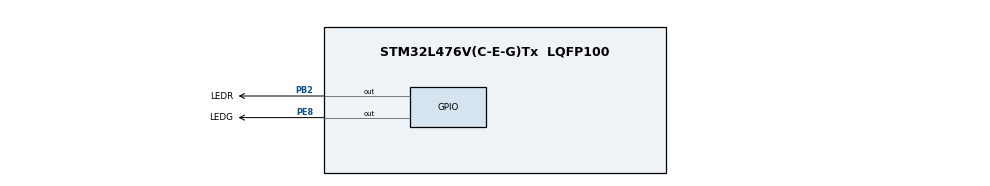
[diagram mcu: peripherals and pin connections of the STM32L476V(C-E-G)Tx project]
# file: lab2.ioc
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Mcu.Family=STM32L4
Mcu.Name=STM32L476V(C-E-G)Tx
Mcu.Package=LQFP100
NVIC.PriorityGroup=NVIC_PRIORITYGROUP_4
NVIC.RNG_IRQn=true\:0\:0\:false\:false\:true\:true\:true
NVIC.TIM2_IRQn=true\:0\:0\:false\:false\:true\:true\:true
NVIC.TIM4_IRQn=true\:0\:0\:false\:false\:true\:true\:true
PB2.GPIO_Label=LEDR
PB2.Signal=GPIO_Output
PE8.GPIO_Label=LEDG
PE8.Signal=GPIO_Output
ProjectManager.HeapSize=0x200
ProjectManager.StackSize=0x400
ProjectManager.TargetToolchain=MDK-ARM V5.27
RCC.ADCFreq_Value=32000000
RCC.CortexFreq_Value=4000000
RCC.HSE_VALUE=8000000
RCC.HSI_VALUE=16000000
RCC.LSE_VALUE=32768
RCC.MSI_VALUE=4000000
RCC.PLLSAI1N=16
RCC.PREFETCH_ENABLE=1
RCC.USBFreq_Value=32000000
RCC.VCOOutputFreq_Value=32000000
TIM2.AutoReloadPreload=TIM_AUTORELOAD_PRELOAD_ENABLE
TIM2.Period=4999
TIM2.Prescaler=399
TIM4.AutoReloadPreload=TIM_AUTORELOAD_PRELOAD_ENABLE
TIM4.Channel-Output\ Compare2\ No\ Output=TIM_CHANNEL_2
TIM4.OC2Preload=ENABLE
TIM4.Prescaler=399
TIM4.Pulse-Output\ Compare2\ No\ Output=9999
VP_RNG_VS_RNG.Mode=RNG_Activate
VP_TIM2_VS_ClockSourceINT.Mode=Internal
VP_TIM4_VS_ClockSourceINT.Mode=Internal
VP_TIM4_VS_no_output2.Mode=Output Compare2 No Output
board=STM32L476G-DISCO

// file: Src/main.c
/* USER CODE BEGIN Header */
/**
  ******************************************************************************
  * @file           : main.c
  * @brief          : Main program body
  ******************************************************************************
  * @attention
  *
  * <h2><center>&copy; Copyright (c) 2020 STMicroelectronics.
  * All rights reserved.</center></h2>
  *
  * This software component is licensed by ST under BSD 3-Clause license,
  * the "License"; You may not use this file except in compliance with the
  * License. You may obtain a copy of the License at:
  *                        opensource.org/licenses/BSD-3-Clause
  *
  ******************************************************************************
  */
/*

*/
/* USER CODE END Header */
#include "main.h"

/* USER CODE BEGIN Includes */
#include "stm32l476g_discovery.h"
#include "stm32l476g_discovery_glass_lcd.h"
#include "eeprom.h"
/* USER CODE END Includes */

typedef enum{DEFAULT, PURGATORY, START} state_Track;		//States for Reaction time tester

RNG_HandleTypeDef hrng;

TIM_HandleTypeDef htim2;
TIM_HandleTypeDef htim4;

/* USER CODE BEGIN PV */
// the emulated EEPROM can save 3 variables at these three addresses
uint16_t VirtAddVarTab[NB_OF_VAR] = {0x5555, 0x6666, 0x7777};
uint16_t counter = 0;
char lcd_buffer[6];
uint32_t rand_Num;
uint16_t time_Elapsed = 0;
uint16_t time_Elapsed_msec = 0;
uint16_t record_Time = 34463;
state_Track state = DEFAULT;

char time_Elapsed_String[6] = "000000";
char rand_Num_String[6] = "000000";
char record_Time_String[6] = "000000";

int sprintf(char *str, const char *format, ...);
/* USER CODE END PV */

void SystemClock_Config(void);
static void MX_GPIO_Init(void);
static void MX_TIM4_Init(void);
static void MX_TIM2_Init(void);
static void MX_RNG_Init(void);

/* USER CODE BEGIN 0 */

void HAL_TIM_PeriodElapsedCallback(TIM_HandleTypeDef *htim)
{
	time_Elapsed++;
	if (state == PURGATORY){
		if (time_Elapsed >= rand_Num){
			time_Elapsed = 0;
			BSP_LCD_GLASS_Clear();
			state = START;
		}
	}else if(state == START){
		BSP_LED_On(LED4);
		BSP_LED_On(LED5);
		time_Elapsed_msec = 10*time_Elapsed;
		sprintf(time_Elapsed_String, "%u", time_Elapsed_msec);
		BSP_LCD_GLASS_DisplayString((uint8_t*)time_Elapsed_String);
	}
}

//Handles frequency change of LED4
void HAL_TIM_OC_DelayElapsedCallback(TIM_HandleTypeDef * htim)
{
	if (state == DEFAULT){
		BSP_LED_Toggle(LED4);
		BSP_LED_Toggle(LED5);
	}else{
		BSP_LED_Off(LED4);
		BSP_LED_Off(LED5);
	}
	__HAL_TIM_SET_COUNTER(htim, 0x0000);
}
/* USER CODE END 0 */

int main(void)
{

  /* MCU Configuration--------------------------------------------------------*/

  /* Reset of all peripherals, Initializes the Flash interface and the Systick. */
  HAL_Init();

  /* Configure the system clock*/
  SystemClock_Config();

	HAL_InitTick(0x0000); //set the systick interrupt priority to the highest

	BSP_LED_Init(LED4);
	BSP_LED_Init(LED5);

	BSP_LCD_GLASS_Init();

	BSP_JOY_Init(JOY_MODE_EXTI);

  /* Initialize all configured peripherals */
  MX_GPIO_Init();
  MX_TIM4_Init();
  MX_TIM2_Init();
  MX_RNG_Init();
  /* USER CODE BEGIN 2 */
	HAL_FLASH_Unlock(); //First unlock flash program erase controller

	//EEPROM INIT
	EE_Init();
	EE_WriteVariable(VirtAddVarTab[2],9999);
	EE_ReadVariable(VirtAddVarTab[2], &counter);
	sprintf(lcd_buffer,"%d", counter);

	BSP_LCD_GLASS_DisplayString((uint8_t*)"MT3TA4");
  /* USER CODE END 2 */

  /* Infinite loop */
  while (1)
  {

  }
}

void SystemClock_Config(void)
{
  RCC_OscInitTypeDef RCC_OscInitStruct = {0};
  RCC_ClkInitTypeDef RCC_ClkInitStruct = {0};
  RCC_PeriphCLKInitTypeDef PeriphClkInit = {0};

  /** Initializes the RCC Oscillators according to the specified parameters
  * in the RCC_OscInitTypeDef structure.
  */
  RCC_OscInitStruct.OscillatorType = RCC_OSCILLATORTYPE_MSI;
  RCC_OscInitStruct.MSIState = RCC_MSI_ON;
  RCC_OscInitStruct.MSICalibrationValue = 0;
	//SYSTEM CLOCK set to 4MHz
  RCC_OscInitStruct.MSIClockRange = RCC_MSIRANGE_6;
  RCC_OscInitStruct.PLL.PLLState = RCC_PLL_NONE;
  if (HAL_RCC_OscConfig(&RCC_OscInitStruct) != HAL_OK)
  {
    Error_Handler();
  }
  /** Initializes the CPU, AHB and APB buses clocks
  */
  RCC_ClkInitStruct.ClockType = RCC_CLOCKTYPE_HCLK|RCC_CLOCKTYPE_SYSCLK
                              |RCC_CLOCKTYPE_PCLK1|RCC_CLOCKTYPE_PCLK2;
  RCC_ClkInitStruct.SYSCLKSource = RCC_SYSCLKSOURCE_MSI;
  RCC_ClkInitStruct.AHBCLKDivider = RCC_SYSCLK_DIV1;
  RCC_ClkInitStruct.APB1CLKDivider = RCC_HCLK_DIV1;
  RCC_ClkInitStruct.APB2CLKDivider = RCC_HCLK_DIV1;

  if (HAL_RCC_ClockConfig(&RCC_ClkInitStruct, FLASH_LATENCY_0) != HAL_OK)
  {
    Error_Handler();
  }
  PeriphClkInit.PeriphClockSelection = RCC_PERIPHCLK_RNG;
  PeriphClkInit.RngClockSelection = RCC_RNGCLKSOURCE_PLLSAI1;
  PeriphClkInit.PLLSAI1.PLLSAI1Source = RCC_PLLSOURCE_MSI;
  PeriphClkInit.PLLSAI1.PLLSAI1M = 1;
  PeriphClkInit.PLLSAI1.PLLSAI1N = 16;
  PeriphClkInit.PLLSAI1.PLLSAI1P = RCC_PLLP_DIV7;
  PeriphClkInit.PLLSAI1.PLLSAI1Q = RCC_PLLQ_DIV2;
  PeriphClkInit.PLLSAI1.PLLSAI1R = RCC_PLLR_DIV2;
  PeriphClkInit.PLLSAI1.PLLSAI1ClockOut = RCC_PLLSAI1_48M2CLK;
  if (HAL_RCCEx_PeriphCLKConfig(&PeriphClkInit) != HAL_OK)
  {
    Error_Handler();
  }
  /** Configure the main internal regulator output voltage
  */
  if (HAL_PWREx_ControlVoltageScaling(PWR_REGULATOR_VOLTAGE_SCALE1) != HAL_OK)
  {
    Error_Handler();
  }
}

static void MX_RNG_Init(void)
{

  hrng.Instance = RNG;
  if (HAL_RNG_Init(&hrng) != HAL_OK)
  {
    Error_Handler();
  }

}

static void MX_TIM2_Init(void)
{

  TIM_ClockConfigTypeDef sClockSourceConfig = {0};
  TIM_MasterConfigTypeDef sMasterConfig = {0};

  htim2.Instance = TIM2;
  htim2.Init.Prescaler = 399;
  htim2.Init.CounterMode = TIM_COUNTERMODE_UP;
  htim2.Init.Period = 99;
  htim2.Init.ClockDivision = TIM_CLOCKDIVISION_DIV1;
  htim2.Init.AutoReloadPreload = TIM_AUTORELOAD_PRELOAD_ENABLE;
  if (HAL_TIM_Base_Init(&htim2) != HAL_OK)
  {
    Error_Handler();
  }
  sClockSourceConfig.ClockSource = TIM_CLOCKSOURCE_INTERNAL;
  if (HAL_TIM_ConfigClockSource(&htim2, &sClockSourceConfig) != HAL_OK)
  {
    Error_Handler();
  }
  sMasterConfig.MasterOutputTrigger = TIM_TRGO_RESET;
  sMasterConfig.MasterSlaveMode = TIM_MASTERSLAVEMODE_DISABLE;
  if (HAL_TIMEx_MasterConfigSynchronization(&htim2, &sMasterConfig) != HAL_OK)
  {
    Error_Handler();
  }
  /* USER CODE BEGIN TIM2_Init 2 */
	if(HAL_TIM_Base_Start_IT(&htim2) != HAL_OK){
		Error_Handler();
	}
  /* USER CODE END TIM2_Init 2 */

}

static void MX_TIM4_Init(void)
{

  TIM_ClockConfigTypeDef sClockSourceConfig = {0};
  TIM_MasterConfigTypeDef sMasterConfig = {0};
  TIM_OC_InitTypeDef sConfigOC = {0};

  htim4.Instance = TIM4;
  htim4.Init.Prescaler = 399;
  htim4.Init.CounterMode = TIM_COUNTERMODE_UP;
  htim4.Init.Period = 9999;
  htim4.Init.ClockDivision = TIM_CLOCKDIVISION_DIV1;
  htim4.Init.AutoReloadPreload = TIM_AUTORELOAD_PRELOAD_ENABLE;
  if (HAL_TIM_Base_Init(&htim4) != HAL_OK)
  {
    Error_Handler();
  }
  sClockSourceConfig.ClockSource = TIM_CLOCKSOURCE_INTERNAL;
  if (HAL_TIM_ConfigClockSource(&htim4, &sClockSourceConfig) != HAL_OK)
  {
    Error_Handler();
  }
  if (HAL_TIM_OC_Init(&htim4) != HAL_OK)
  {
    Error_Handler();
  }
  sMasterConfig.MasterOutputTrigger = TIM_TRGO_RESET;
  sMasterConfig.MasterSlaveMode = TIM_MASTERSLAVEMODE_DISABLE;
  if (HAL_TIMEx_MasterConfigSynchronization(&htim4, &sMasterConfig) != HAL_OK)
  {
    Error_Handler();
  }
  sConfigOC.OCMode = TIM_OCMODE_TIMING;
  sConfigOC.Pulse = 9999;
  sConfigOC.OCPolarity = TIM_OCPOLARITY_HIGH;
  sConfigOC.OCFastMode = TIM_OCFAST_DISABLE;
  if (HAL_TIM_OC_ConfigChannel(&htim4, &sConfigOC, TIM_CHANNEL_2) != HAL_OK)
  {
    Error_Handler();
  }
  __HAL_TIM_ENABLE_OCxPRELOAD(&htim4, TIM_CHANNEL_2);
  /* USER CODE BEGIN TIM4_Init 2 */
	if (HAL_TIM_OC_Start_IT(&htim4, TIM_CHANNEL_2) != HAL_OK)
	{
		/*Starting Error*/
		Error_Handler();
	}
  /* USER CODE END TIM4_Init 2 */

}

static void MX_GPIO_Init(void)
{
	//set all joy pin interupts to highest peripheral interupt priority -> 0
	//Ensures Joy Pin interupts will be prioritized as timing is critical
	//in the application they are being used for
	HAL_NVIC_SetPriority(EXTI0_IRQn, 0, 0);
	HAL_NVIC_SetPendingIRQ(EXTI0_IRQn);

	HAL_NVIC_SetPriority(EXTI1_IRQn, 0, 0);
	HAL_NVIC_SetPendingIRQ(EXTI1_IRQn);

	HAL_NVIC_SetPriority(EXTI2_IRQn, 0, 0);
	HAL_NVIC_SetPendingIRQ(EXTI2_IRQn);

	HAL_NVIC_SetPriority(EXTI3_IRQn, 0, 0);
	HAL_NVIC_SetPendingIRQ(EXTI3_IRQn);

	HAL_NVIC_SetPriority(EXTI9_5_IRQn, 0, 0);
	HAL_NVIC_SetPendingIRQ(EXTI9_5_IRQn);

  GPIO_InitTypeDef GPIO_InitStruct = {0};

  /* GPIO Ports Clock Enable */
  __HAL_RCC_GPIOB_CLK_ENABLE();
  __HAL_RCC_GPIOE_CLK_ENABLE();

  /*Configure GPIO pin Output Level */
  HAL_GPIO_WritePin(LEDR_GPIO_Port, LEDR_Pin, GPIO_PIN_RESET);

  /*Configure GPIO pin Output Level */
  HAL_GPIO_WritePin(LEDG_GPIO_Port, LEDG_Pin, GPIO_PIN_RESET);

  /*Configure GPIO pin : LEDR_Pin */
  GPIO_InitStruct.Pin = LEDR_Pin;
  GPIO_InitStruct.Mode = GPIO_MODE_OUTPUT_PP;
  GPIO_InitStruct.Pull = GPIO_NOPULL;
  GPIO_InitStruct.Speed = GPIO_SPEED_FREQ_LOW;
  HAL_GPIO_Init(LEDR_GPIO_Port, &GPIO_InitStruct);

  /*Configure GPIO pin : LEDG_Pin */
  GPIO_InitStruct.Pin = LEDG_Pin;
  GPIO_InitStruct.Mode = GPIO_MODE_OUTPUT_PP;
  GPIO_InitStruct.Pull = GPIO_NOPULL;
  GPIO_InitStruct.Speed = GPIO_SPEED_FREQ_LOW;
  HAL_GPIO_Init(LEDG_GPIO_Port, &GPIO_InitStruct);

}

/* USER CODE BEGIN 4 */
void HAL_GPIO_EXTI_Callback(uint16_t GPIO_Pin){
	switch (GPIO_Pin){
		//Right Joy Pin forces state default
		//Restore MT3TA4 to screen
		//Acts like a home button exiting the game no matter the current conditions ie) state
		case (GPIO_PIN_2):
		{
			state = DEFAULT;
			BSP_LCD_GLASS_Clear();
			BSP_LCD_GLASS_DisplayString((uint8_t*)"MT3TA4");
			break;
		}
		//Joy Pins left, select, and down all operate in the same manner
		//all  trigger state = wait on first press
		//all trigger "CHEAT" if pressed during PURGATORY
		//all trigger the time to stop is pressed during START
		case (GPIO_PIN_0):
		case (GPIO_PIN_1):
		case (GPIO_PIN_5):
			{
				switch(state)
					{
					//DEFAULT state
					case (DEFAULT):
						{
						//aquire a true random value using HAL_RNG_GetRandomNumber(&hrng);
						rand_Num = HAL_RNG_GetRandomNumber(&hrng);
						//assign remainder from int division by 4000 to self -> divide by 10 for resolution deficiency
						rand_Num = (rand_Num % 4000)/10;
						BSP_LCD_GLASS_Clear();
						BSP_LCD_GLASS_DisplayString((uint8_t*)"WAIT");
						//turn off LEDS per requirement document
						BSP_LED_Off(LED4);
						BSP_LED_Off(LED5);
						//set time_Elapsed = 0 -> RNG wait time will be compared against time_Elapsed as it counts up
						//until time_Elapsed >= RNG wait time
						time_Elapsed = 0;
						//State called "PURGATORY" is set so that cheat detection is enabled
						state = PURGATORY;
						break;
						}
					//Waiting Period
					case (PURGATORY):
						{
						//If button is pressed prior to time_Elapsed >= RNG Wait time (rand_Num)
						//message "CHEAT" is displayed and state DEFAULT is restored effectively terminating the turn
						BSP_LCD_GLASS_Clear();
						BSP_LCD_GLASS_DisplayString((uint8_t*)"CHEAT");
						state = DEFAULT;
						break;
						}
					//Game Begins
					case (START):
						{
							//read the current high score and save in record_Time
							EE_ReadVariable(VirtAddVarTab[0], &record_Time);
							//if time just scored is less than  record_Time (whih is preset to
							if(time_Elapsed_msec < record_Time)
							{
							record_Time = time_Elapsed_msec;
							}
						EE_WriteVariable(VirtAddVarTab[0], record_Time);
						state = DEFAULT;
						break;
						}
				}
				break;
			}
		//UP
		case (GPIO_PIN_3):
		{
			//states are tested on up joy pin interrupt so that high score is not displayed during a game
			//also enables up joy pin to be used as a stopping interupt
			//That is to say it will stop the clock for reaction time or display cheat if pressed during PURGATORY state
				switch(state)
				{
					//DEFAULT
					case (DEFAULT):
					{
						//When up Joy Pin is pressed current high score is read from emulated EEPROM
						//We store current high score in first memory location [0]
						BSP_LCD_GLASS_Clear();
						EE_ReadVariable(VirtAddVarTab[0], &record_Time);
						sprintf(record_Time_String, "%u", record_Time);
						BSP_LCD_GLASS_Clear();
						BSP_LCD_GLASS_DisplayString((uint8_t*)record_Time_String);
						break;
					}
					//if up pin is pressed during PURGATORY cheat is displayed
					//prevents high score from displaying during wait
					case (PURGATORY):
					{
						BSP_LCD_GLASS_Clear();
						BSP_LCD_GLASS_DisplayString((uint8_t*)"CHEAT");
						state = DEFAULT;
						break;
					}
					//if up pin is pressed during START timer is stopped and time is compared to highscore
					//acts same as if left, down, or select was pressed
					//prevents high score from displaying during game
					case (START):
					{
						EE_ReadVariable(VirtAddVarTab[0], &record_Time);
						if(time_Elapsed_msec < record_Time || record_Time == 0x00)
							{
							record_Time = time_Elapsed_msec;
							}
						EE_WriteVariable(VirtAddVarTab[0], record_Time);
						state = DEFAULT;
						break;
					}
				}
				break;
		}
	}
}
	/*
		//LEFT
		case (GPIO_PIN_1):{
				counter = 100;
				EE_WriteVariable(VirtAddVarTab[2], counter);
				sprintf(lcd_buffer, "%d", counter);
				BSP_LCD_GLASS_Clear();
				BSP_LCD_GLASS_DisplayString((uint8_t*)lcd_buffer);
				break;}

		//RIGHT
		case (GPIO_PIN_2):{
				counter = 200;
				EE_WriteVariable(VirtAddVarTab[2], counter);
				sprintf(lcd_buffer, "%d", counter);
				BSP_LCD_GLASS_Clear();
				BSP_LCD_GLASS_DisplayString((uint8_t*)lcd_buffer);
				break;}

		//DOWN
		case (GPIO_PIN_5):{
				BSP_LCD_GLASS_Clear();
				break;}

		default:{
			//default display
				BSP_LCD_GLASS_Clear();
				BSP_LCD_GLASS_DisplayString((uint8_t*)"ERROR");
				break
*/

/* USER CODE END 4 */

void Error_Handler(void)
{
}

/************************ (C) COPYRIGHT STMicroelectronics *****END OF FILE****/
